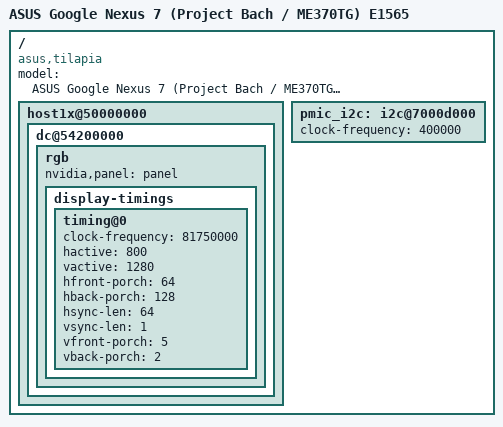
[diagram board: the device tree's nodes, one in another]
// SPDX-License-Identifier: GPL-2.0-or-later
/dts-v1/;

#include <dt-bindings/input/gpio-keys.h>
#include <dt-bindings/input/linux-event-codes.h>

#include "tegra30-asus-grouper-common.dtsi"

/ {
	model = "ASUS Google Nexus 7 (Project Bach / ME370TG) E1565";
	compatible = "asus,tilapia", "nvidia,tegra30";

	host1x@50000000 {
		status = "okay";
		dc@54200000 {
			status = "okay";
			rgb {
				status = "okay";

				nvidia,panel = <&panel>;

				display-timings {
					timing@0 {
						/* 1280x800@60Hz */
						clock-frequency = <81750000>;
						hactive = <800>;
						vactive = <1280>;
						hfront-porch = <64>;
						hback-porch = <128>;
						hsync-len = <64>;
						vsync-len = <1>;
						vfront-porch = <5>;
						vback-porch = <2>;
					};
				};
			};
		};
	};

	pmic_i2c: i2c@7000d000 {
		status = "okay";
		clock-frequency = <400000>;
	};
};
